# LPC54S018M register map
Vendor: nxp.com; File version: 1.0
CPU: CM4 r0p1, little endian, MPU, FPU, VTOR, 3 interrupt priority bits
Registers are 32-bit, read-write, reset 0x0 unless marked. A register's access mark holds for its fields unless they carry their own. Offsets are from the block's base; [hi:lo] are bit positions; lines under a group give offsets from that group; {n}, {i} and the like mark numbered series.

## ENET — LPC54S60x/LPC5460x Ethernet controller
Base 0x40092000
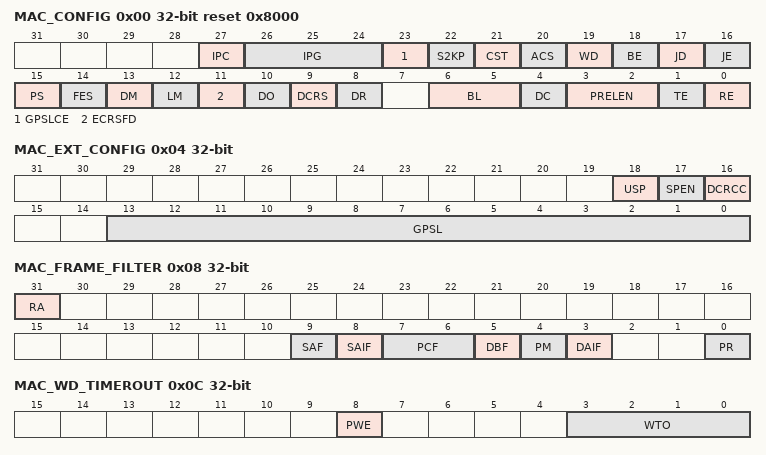
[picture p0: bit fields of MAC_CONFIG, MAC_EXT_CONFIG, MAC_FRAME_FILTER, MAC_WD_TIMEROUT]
0x00 MAC_CONFIG reset 0x8000 — MAC configuration register
  [27] IPC — Checksum Offload When set, this bit enables the IPv4 header checksum checking and IPv4 or IPv6 TCP, UDP, or ICMP payload checksum checking.
  [26:24] IPG — Inter-Packet Gap These bits control the minimum IPG between packets during transmission.
  [23] GPSLCE — Giant Packet Size Limit Control Enable When this bit is set, the MAC considers the value in GPSL field in MAC Ext Configuration register to declare a received packet as Giant packet.
  [22] S2KP — IEEE 802.
  [21] CST — CRC stripping for Type packets When this bit is set, the last four bytes (FCS) of all packets of Ether type (type field greater than 1,536) are stripped and dropped before forwarding the packet to the application.
  [20] ACS — Automatic Pad or CRC Stripping When this bit is set, the MAC strips the Pad or FCS field on the incoming packets only if the value of the length field is less than 1,536 bytes.
  [19] WD — Watchdog Disable When this bit is set, the MAC disables the watchdog timer on the receiver, and can receive frames of up to 16,384 bytes.
  [18] BE — Packet Burst Enable When this bit is set, the MAC allows packet bursting during transmission in the MII half-duplex mode.
  [17] JD — Jabber Disable When this bit is set, the MAC disables the jabber timer on the transmitter, and can transfer frames of up to 16,384 bytes.
  [16] JE — Jumbo Frame Enable When this bit is set, MAC allows Jumbo frames of 9,018 bytes (9,022 bytes for tagged frames) without reporting a giant frame error in the receive frame status.
  [15] PS ro — Portselect.
  [14] FES — Speed Indicates the speed in Fast Ethernet (MII) mode: This bit is reserved (RO) by default and is enabled only when RMII/SMII is enabled during configuration.
  [13] DM — Duplex Mode When this bit is set, the MAC operates in a Full-Duplex mode where it can transmit and receive simultaneously.
  [12] LM — Loopback Mode When this bit is set, the MAC operates in loopback mode at MII.
  [11] ECRSFD — Enable Carrier Sense Before Transmission in Full-Duplex Mode When this bit is set, the MAC transmitter checks the CRS signal before packet transmission in the full-duplex mode.
  [10] DO — Disable Receive Own When this bit is set, the MAC disables the reception of frames when the gmii_txen_o is asserted in Half-Duplex mode.
  [9] DCRS — Disable Carrier Sense During Transmission When this bit is set, the MAC transmitter ignores the MII CRS signal during packet transmission in the half-duplex mode.
  [8] DR — Disable Retry When this bit is set, the MAC will attempt only one transmission.
  [6:5] BL — Back-Off Limit The Back-Off limit determines the random integer number (r) of slot time delays (4,096 bit times for 1000 Mbps and 512 bit times for 10/100 Mbps) the MAC waits before rescheduling a transmission attempt during retries after a collision.
  [4] DC — Deferral Check When this bit is set, the deferral check function is enabled in the MAC.
  [3:2] PRELEN — Preamble Length for Transmit packets These bits control the number of preamble bytes that are added to the beginning of every Tx packet.
  [1] TE — Transmitter Enable When this bit is set, the transmit state machine of the MAC is enabled for transmission on the MII.
  [0] RE — Receiver Enable When this bit is set, the receiver state machine of the MAC is enabled for receiving frames from the MII.
0x04 MAC_EXT_CONFIG
  [18] USP — Unicast Slow Protocol Packet Detect When this bit is set, the MAC detects the Slow Protocol packets with unicast address of the station specified in the MAC Address High Table 747 and MAC Address Low Table 748 registers.
  [17] SPEN — Slow Protocol Detection Enable When this bit is set, MAC processes the Slow Protocol packets (Ether Type 0x8809) and provides the Rx status.
  [16] DCRCC — Disable CRC Checking for Received Packets When this bit is set, the MAC receiver does not check the CRC field in the received packets.
  [13:0] GPSL — Giant Packet Size Limit If the received packet size is greater than the value programmed in this field in units of bytes, the MAC declares the received packet as Giant packet.
0x08 MAC_FRAME_FILTER
  [31] RA — Receive all When this bit is set, the MAC Receiver module passes to the Application all frames received irrespective of whether they pass the address filter.
  [9] SAF ro — Source Address Filter Enable When this bit is set, the MAC compares the SA field of the received packets with the values programmed in the enabled SA registers.
  [8] SAIF ro — SA Inverse Filtering When this bit is set, the Address Check block operates in the inverse filtering mode for SA address comparison.
  [7:6] PCF — Pass Control Frames These bits control the forwarding of all control frames (including unicast and multicast PAUSE frames).
  [5] DBF — Disable Broadcast Frames When this bit is set, the AFM module filters all incoming broadcast frames.
  [4] PM — Pass All Multicast When set, this bit indicates that all received frames with a multicast destination address (first bit in the destination address field is '1') are passed.
  [3] DAIF — DA Inverse Filtering When this bit is set, the Address Check block operates in inverse filtering mode for the DA address comparison for both unicast and multicast frames.
  [0] PR — Promiscuous Mode When this bit is set, the Address Filter module passes all incoming frames regardless of its destination or source address.
0x0C MAC_WD_TIMEROUT — MAC watchdog Timeout register
  [8] PWE — Programmable Watchdog Enable When this bit is set and the WD bit of the MAC Configuration register Table 722 is reset, the WTO field is used as watchdog timeout for a received packet.
  [3:0] WTO — Watchdog Timeout When the PWE bit is set and the WD bit of the MAC Configuration register Table 722 is reset, this field is used as watchdog timeout for a received packet.
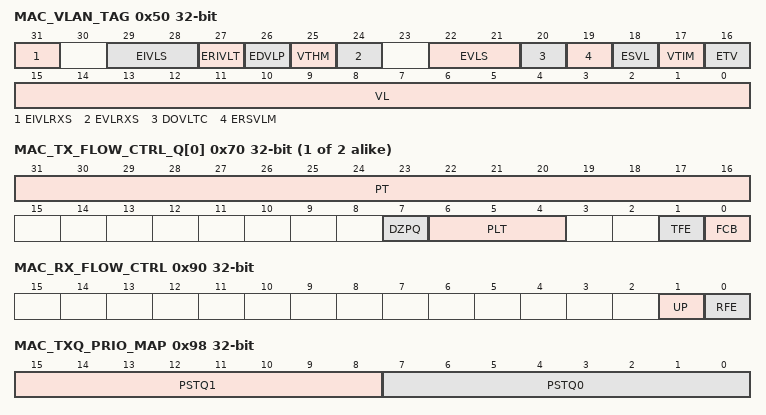
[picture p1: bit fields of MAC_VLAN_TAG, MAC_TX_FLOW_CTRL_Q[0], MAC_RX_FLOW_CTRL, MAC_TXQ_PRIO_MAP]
0x50 MAC_VLAN_TAG (reset mask 0xFFFF)
  [31] EIVLRXS — Enable Inner VLAN Tag in Rx Status.
  [29:28] EIVLS — Enable Inner VLAN Tag Stripping on Receive.
  [27] ERIVLT — Enable Inner VLAN Tag.
  [26] EDVLP — Enable Double VLAN Processing.
  [25] VTHM — Disable VLAN Type Check.
  [24] EVLRXS — Enable VLAN Tag in Rx status.
  [22:21] EVLS — Enable VLAN Tag Stripping on Receive.
  [20] DOVLTC — Disable VLAN Type Check.
  [19] ERSVLM — Enable Receive S-VLAN Match.
  [18] ESVL — Enable S-VLAN.
  [17] VTIM — VLAN Tag Inverse Match Enable.
  [16] ETV — Enable 12-Bit VLAN Tag Comparison.
  [15:0] VL — VLAN Tag Identifier for Receive Packets.
{0x70+4i} MAC_TX_FLOW_CTRL_Q[{i}] (i=0..1) — Transmit flow control register
  [31:16] PT — Pause time This field holds the value to be used in the Pause Time field in the transmit control frame.
  [7] DZPQ — Disable Zero-Quanta Pause When set, this bit disables the automatic generation of Zero-Quanta Pause Control frames on the deassertion of the flow-control signal from the FIFO layer.
  [6:4] PLT — Pause Low Threshold This field configures the threshold of the PAUSE timer at which the input flow control signal is checked for automatic retransmission of PAUSE Frame.
  [1] TFE — Transmit Flow Control Enable In Full-Duplex mode, when this bit is set, the MAC enables the flow control operation to transmit Pause frames.
  [0] FCB — Flow Control Busy/Backpressure Activate This register field can be read by the application (Read), can be set to 1 by the application with a register write of 1 (Write Set), and is cleared to 0 by the core (Self Clear).
0x90 MAC_RX_FLOW_CTRL — Receive flow control register
  [1] UP — Unicast Pause Packet Detect A pause packet is processed when it has the unique multicast address specified in the IEEE 802.
  [0] RFE — Receive Flow Control Enable When this bit is set and the MAC is operating in full-duplex mode, the MAC decodes the received Pause packet and disables its transmitter for a specified (Pause) time.
0x98 MAC_TXQ_PRIO_MAP
  [15:8] PSTQ1 — Priorities Selected in Transmit Queue 1 This bit is similar to the PSTQ0 bit.
  [7:0] PSTQ0 — Priorities Selected in Transmit Queue 0 This field holds the priorities assigned to Tx Queue 0 by the software.
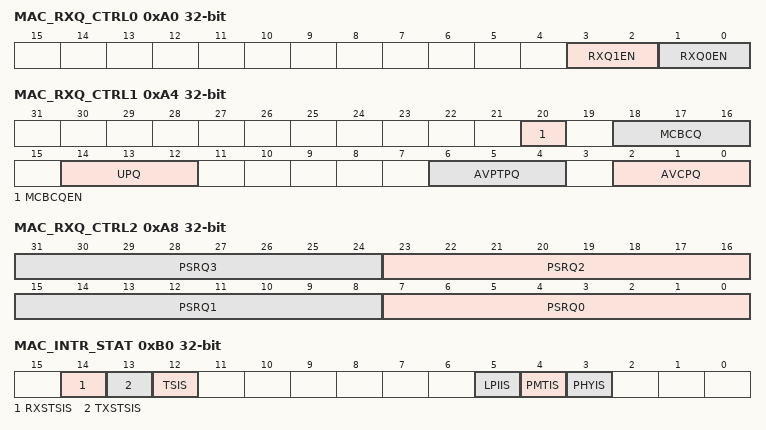
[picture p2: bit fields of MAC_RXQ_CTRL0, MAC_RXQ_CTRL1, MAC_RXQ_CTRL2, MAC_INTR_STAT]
0xA0 MAC_RXQ_CTRL0 — Receive Queue Control 0 register 0x0000
  [3:2] RXQ1EN — Receive Queue 1 Enable.
  [1:0] RXQ0EN — Receive Queue 0 Enable.
0xA4 MAC_RXQ_CTRL1 — Receive Queue Control 0 register 0x0000
  [20] MCBCQEN — Multicast and Broadcast Queue Enable.
  [18:16] MCBCQ — Multicast and Broadcast Queue.
  [14:12] UPQ — Untagged Packet Queue.
  [6:4] AVPTPQ — AV PTP Packets Queue.
  [2:0] AVCPQ — AV Untagged Control Packets Queue.
0xA8 MAC_RXQ_CTRL2 — Receive Queue Control 0 register 0x0000
  [8n+7:8n] PSRQ{n} (n=0..3) — Priorities Selected in the Receive Queue {n}.
0xB0 MAC_INTR_STAT ro — Interrupt status register 0x0000
  [14] RXSTSIS — Receive Status Interrupt.
  [13] TXSTSIS — Transmit Status Interrupt.
  [12] TSIS — Timestamp interrupt status.
  [5] LPIIS — LPI Interrupt Status.
  [4] PMTIS — PMT Interrupt Status.
  [3] PHYIS — PHY Interrupt.
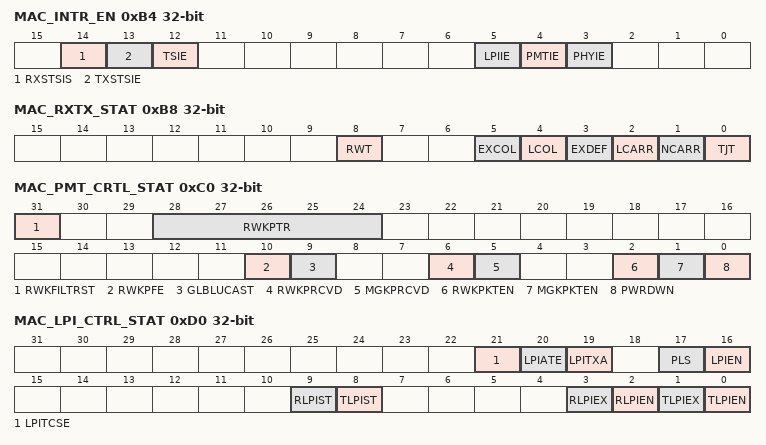
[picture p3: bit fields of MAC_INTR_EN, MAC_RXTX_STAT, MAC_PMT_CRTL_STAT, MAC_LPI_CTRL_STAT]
0xB4 MAC_INTR_EN — Interrupt enable register 0x0000
  [14] RXSTSIS — Receive Status Interrupt Enable.
  [13] TXSTSIE — Transmit Status Interrupt Enable.
  [12] TSIE — Timestamp Interrupt Enable.
  [5] LPIIE — LPI Interrupt Enable.
  [4] PMTIE — PMT Interrupt Enable.
  [3] PHYIE — PHY Interrupt Enable.
0xB8 MAC_RXTX_STAT ro — Receive Transmit Status register
  [8] RWT — Receive Watchdog Timeout This bit is set when a packet with length greater than 2,048 bytes is received (10,240 bytes when Jumbo Packet mode is enabled) and the WD bit is reset in the MAC Configuration register Table 722.
  [5] EXCOL — Excessive Collisions When the DTXSTS bit is set in the MTL Operation Mode register Table 758, this bit indicates that the transmission aborted after 16 successive collisions while attempting to transmit the current packet.
  [4] LCOL — Late Collision When the DTXSTS bit is set in the MTL Operation Mode register Table 758, this bit indicates that the packet transmission aborted because a collision occurred after the collision window (64 bytes including Preamble in MII mode).
  [3] EXDEF — Excessive Deferral When the DTXSTS bit is set in the MTL Operation Mode register Table 758 and the DC bit is set in the MAC Configuration register Table 758, this bit indicates that the transmission ended because of excessive deferral of over 24,288 bit times (155,680 when Jumbo packet is enabled).
  [2] LCARR — Loss of Carrier When the DTXSTS bit is set in the MTL Operation Mode register Table 758, this bit indicates that the loss of carrier occurred during packet transmission, that is, the PHY Carrier signal was inactive for one or more transmission clock periods during packet transmission.
  [1] NCARR — No Carrier When the DTXSTS bit is set in the MTL Operation Mode register Table 758, this bit indicates that the carrier signal from the PHY is not present at the end of preamble transmission.
  [0] TJT — PHY Interrupt Enable When this bit is set, it enables the assertion of the interrupt signal because of the setting of PHYIS bit in MAC Interrupt Status register Table 731.
0xC0 MAC_PMT_CRTL_STAT
  [31] RWKFILTRST — Remote Wake-Up Packet Filter Register Pointer Reset When this bit is set, the remote wake-up packet filter register pointer is reset to 3'b000.
  [28:24] RWKPTR — Remote Wake-up FIFO Pointer This field gives the current value (0 to 7) of the Remote Wake-up Packet Filter register pointer.
  [10] RWKPFE — Remote Wake-up Packet Forwarding Enable When this bit is set along with RWKPKTEN, the MAC receiver drops all received frames until it receives the expected wake-up frame.
  [9] GLBLUCAST — Global Unicast When this bit set, any unicast packet filtered by the MAC (DAF) address recognition is detected as a remote wake-up packet.
  [6] RWKPRCVD ro — Remote Wake-Up Packet Received.
  [5] MGKPRCVD ro — Magic Packet Received.
  [2] RWKPKTEN ro — Remote Wake-Up Packet Enable When this bit is set, a power management event is generated when the MAC receives a remote wake-up packet.
  [1] MGKPKTEN ro — Magic Packet Enable.
  [0] PWRDWN ro — Transmit LPI Entry When this bit is set, it indicates that the MAC Transmitter has entered the LPI state because of the setting of the LPIEN bit.
0xC4 MAC_RWAKE_FRFLT — Remote wake-up frame filter
  [31:0] ADDR — WKUPFMFILTER address.
0xD0 MAC_LPI_CTRL_STAT — LPI Control and Status Register
  [21] LPITCSE — LPI Tx Clock Stop Enable When this bit is set, the MAC asserts LPI Tx Clock Gating Control signal high after it enters Tx LPI mode to indicate that the Tx clock to MAC can be stopped.
  [20] LPIATE — LPI Timer Enable This bit controls the automatic entry of the MAC Transmitter into and exit out of the LPI state.
  [19] LPITXA — LPI Tx Automate This bit controls the behavior of the MAC when it is entering or coming out of the LPI mode on the Transmit side.
  [17] PLS — PHY Link Status This bit indicates the link status of the PHY.
  [16] LPIEN — LPI Enable When this bit is set, it instructs the MAC Transmitter to enter the LPI state.
  [9] RLPIST ro — Receive LPI State When this bit is set, it indicates that the MAC is receiving the LPI pattern on the MII interface.
  [8] TLPIST ro — Transmit LPI State When this bit is set, it indicates that the MAC is transmitting the LPI pattern on the MII interface.
  [3] RLPIEX ro — Receive LPI Exit When this bit is set, it indicates that the MAC Receiver has stopped receiving the LPI pattern on the MII interface, exited the LPI state, and resumed the normal reception.
  [2] RLPIEN ro — Receive LPI Entry When this bit is set, it indicates that the MAC Receiver has received an LPI pattern and entered the LPI state.
  [1] TLPIEX ro — Transmit LPI Exit When this bit is set, it indicates that the MAC transmitter exited the LPI state after the application cleared the LPIEN bit and the LPI TW Timer has expired.
  [0] TLPIEN ro — Transmit LPI Entry When this bit is set, it indicates that the MAC Transmitter has entered the LPI state because of the setting of the LPIEN bit.
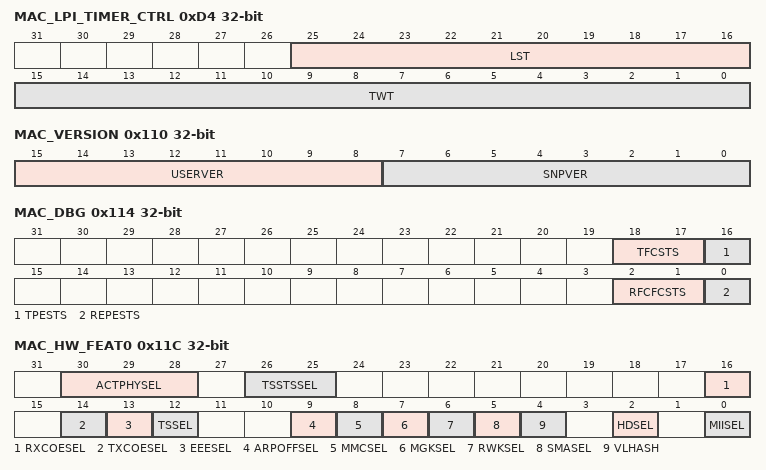
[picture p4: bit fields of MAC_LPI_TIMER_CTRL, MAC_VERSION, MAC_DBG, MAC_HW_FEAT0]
0xD4 MAC_LPI_TIMER_CTRL — LPI Timers Control register
  [25:16] LST — LPI LS Timer This field specifies the minimum time (in milliseconds) for which the link status from the PHY should be up (OKAY) before the LPI pattern can be transmitted to the PHY.
  [15:0] TWT — LPI TW Timer This field specifies the minimum time (in microseconds) for which the MAC waits after it stops transmitting the LPI pattern to the PHY and before it resumes the normal transmission.
0xD8 MAC_LPI_ENTR_TIMR — LPI entry Timer register
  [19:3] LPIET — LPI Entry Timer This field specifies the time in microseconds the MAC will wait to enter LPI mode, after it has transmitted all the frames.
0xDC MAC_1US_TIC_COUNTR
  [11:0] TIC_1US_CNTR — 1US TIC Counter The application must program this counter so that the number of clock cycles of CSR clock is 1us.
0x110 MAC_VERSION ro (reset mask 0x20FF)
  [15:8] USERVER — User defined version.
  [7:0] SNPVER — NXP defined version.
0x114 MAC_DBG ro — MAC debug register
  [18:17] TFCSTS — MAC Transmit Packet Controller Status This field indicates the state of the MAC Transmit Packet Controller module.
  [16] TPESTS — MAC MII Transmit Protocol Engine Status When this bit is set, it indicates that the MAC or MII transmit protocol engine is actively transmitting data, and it is not in the Idle state.
  [2:1] RFCFCSTS — MAC Receive Packet Controller FIFO Status When this bit is set, this field indicates the active state of the small FIFO Read and Write controllers of the MAC Receive Packet Controller module.
  [0] REPESTS — MAC MII Receive Protocol Engine Status When this bit is set, it indicates that the MAC MII receive protocol engine is actively receiving data, and it is not in the Idle state.
0x11C MAC_HW_FEAT0 ro — MAC hardware feature register 0x0201
  [30:28] ACTPHYSEL — Active PHY Selected.
  [26:25] TSSTSSEL — Timestamp System Time Source.
  [16] RXCOESEL — Receive Checksum Offload Support.
  [14] TXCOESEL — Transmit Checksum Offload Support.
  [13] EEESEL — Energy Efficient Ethernet Support .
  [12] TSSEL — IEEE 1588-2008 Timestamp support .
  [9] ARPOFFSEL — ARP Offload Enabled.
  [8] MMCSEL — RMON Module Enable.
  [7] MGKSEL — PMT magic packet detection.
  [6] RWKSEL — PMT Remote Wake-up Packet Detection.
  [5] SMASEL — SMA (MDIO) Interface.
  [4] VLHASH — Hash Table Based Filtering option.
  [2] HDSEL — Half-duplex Support.
  [0] MIISEL — 10 or 100 Mbps Support.
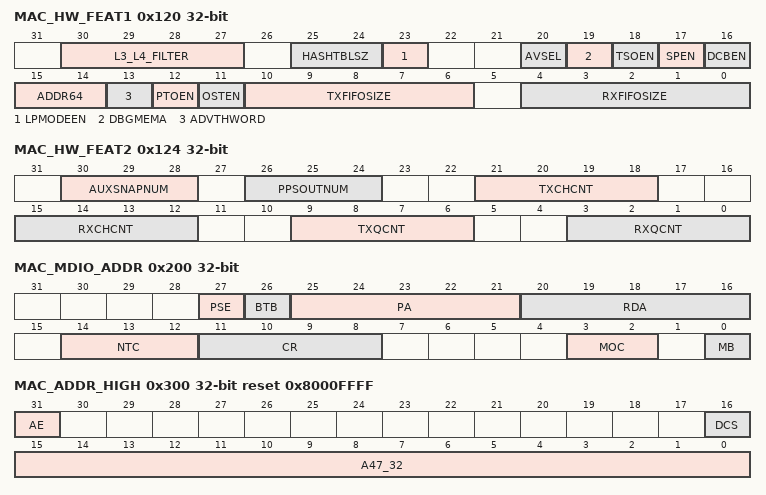
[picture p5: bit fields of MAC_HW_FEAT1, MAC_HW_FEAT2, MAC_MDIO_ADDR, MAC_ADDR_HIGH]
0x120 MAC_HW_FEAT1 ro — MAC hardware feature register 0x0201
  [30:27] L3_L4_FILTER — Total Number of L3 and L4 Filters .
  [25:24] HASHTBLSZ — Hash Table Size.
  [23] LPMODEEN — Low Power Mode Feature Support .
  [20] AVSEL — Audio Video Bridging Feature.
  [19] DBGMEMA — DMA Debug Register Feature.
  [18] TSOEN — TCP Segment Offload Feature.
  [17] SPEN — Split Header Structure feature.
  [16] DCBEN — Data Center Bridging feature.
  [15:14] ADDR64 — Address width.
  [13] ADVTHWORD — IEEE 1588 High Word Register Feature.
  [12] PTOEN — PTP OffLoad Feature.
  [11] OSTEN — One-Step Timestamping Feature.
  [10:6] TXFIFOSIZE — MTL Transmit FIFO Size.
  [4:0] RXFIFOSIZE — MTL Receive FIFO Size.
0x124 MAC_HW_FEAT2 ro — MAC hardware feature register 0x0201
  [30:28] AUXSNAPNUM — Number of Auxiliary Snapshot Inputs.
  [26:24] PPSOUTNUM — Number of PPS Outputs.
  [21:18] TXCHCNT — Number of DMA Transmit Channels.
  [15:12] RXCHCNT — Number of DMA Receive Channels.
  [9:6] TXQCNT — Number of MTL Transmit Queues.
  [3:0] RXQCNT — Number of MTL Receive Queues.
0x200 MAC_MDIO_ADDR — MIDO address Register
  [27] PSE — Preamble Suppression Enable When this bit is set, the SMA will suppress the 32-bit preamble and transmit MDIO frames with only 1 preamble bit.
  [26] BTB — Back to Back transactions When this bit is set and the NTC has value greater than 0, then the MAC will inform the completion of a read or write command at the end of frame transfer (before the trailing clocks are transmitted).
  [25:21] PA — Physical Layer Address This field indicates which PHY devices (out of 32 devices) the MAC is accessing.
  [20:16] RDA — Register/Device Address These bits select the PHY register in selected PHY device.
  [14:12] NTC — Number of Training Clocks This field controls the number of trailing clock cycles generated on MDC after the end of transmission of MDIO frame.
  [11:8] CR — CSR Clock Range.
  [3:2] MOC — MII Operation Command.
  [0] MB — MII busy.
0x204 MAC_MDIO_DATA — MDIO Data register
  [15:0] MD — MII Data This field contains the 16-bit data value read from the PHY after a Management Read operation or the 16-bit data value to be written to the PHY before a Management Write operation.
0x300 MAC_ADDR_HIGH reset 0x8000FFFF — MAC address0 high register
  [31] AE ro — Address Enable.
  [16] DCS — DMA Channel Select This field contains the DMA Channel number to which the Rx packet whose DA matches the MAC Address content is routed.
  [15:0] A47_32 — MAC Address0 [47:32] This field contains the upper 16 bits (47:32) of the 6-byte first MAC address.
0x304 MAC_ADDR_LOW reset 0xFFFFFFFF — MAC address0 low register
  [31:0] A31_0 — MAC Address0 [31:0] This field contains the lower 32 bits of the 6-byte first MAC address.
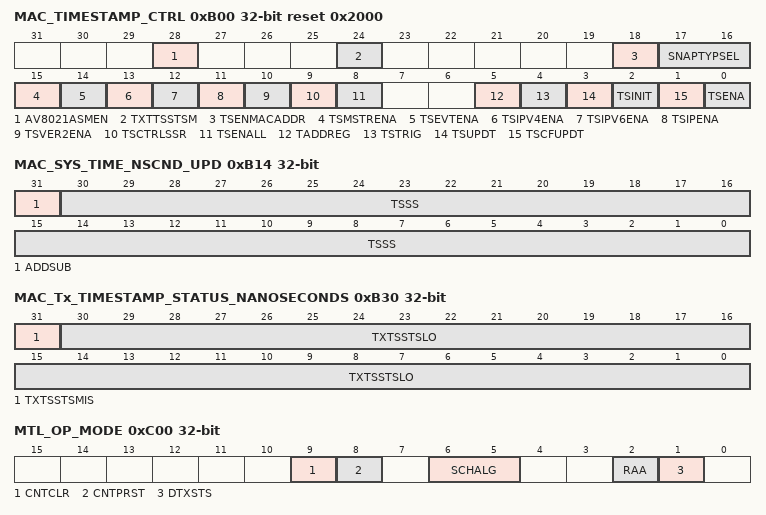
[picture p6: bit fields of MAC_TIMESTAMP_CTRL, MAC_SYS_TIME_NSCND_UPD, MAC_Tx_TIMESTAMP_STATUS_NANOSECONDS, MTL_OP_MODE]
0xB00 MAC_TIMESTAMP_CTRL reset 0x2000 — Time stamp control register
  [28] AV8021ASMEN — AV 802.
  [24] TXTTSSTSM — Transmit Timestamp Status Mode When this bit is set, the MAC overwrites the earlier transmit timestamp status even if it is not read by the software.
  [18] TSENMACADDR — Enable MAC Address for PTP Packet Filtering When this bit is set, the DA MAC address (that matches any MAC Address register) is used to filter the PTP packets when PTP is directly sent over Ethernet.
  [17:16] SNAPTYPSEL — Select PTP packets for Taking Snapshots These bits, along with Bits 15 and 14, decide the set of PTP packet types for which snapshot needs to be taken.
  [15] TSMSTRENA — Enable Snapshot for Messages Relevant to Master When this bit is set, the snapshot is taken only for the messages that are relevant to the master node.
  [14] TSEVTENA — Enable Timestamp Snapshot for Event Messages When this bit is set, the timestamp snapshot is taken only for event messages (SYNC, Delay_Req, Pdelay_Req, or Pdelay_Resp).
  [13] TSIPV4ENA — Enable Processing of PTP Packets Sent over IPv4-UDP When this bit is set, the MAC receiver processes the PTP packets encapsulated in IPv4-UDP packets.
  [12] TSIPV6ENA — Enable Processing of PTP Packets Sent over 1Pv6-UDP When this bit is set, the MAC receiver processes the PTP packets encapsulated in IPv6-UDP packets.
  [11] TSIPENA — Enable Processing of PTP over Ethernet Packets When this bit is set, the MAC receiver processes the PTP packets encapsulated directly in the Ethernet packets.
  [10] TSVER2ENA — Enable PTP Packet Processing for Version 2 Format When this bit is set, the IEEE 1588 version 2 format is used to process the PTP packets.
  [9] TSCTRLSSR — Timestamp Digital or Binary Rollover Control When this bit is set, the Timestamp Low register rolls over after 0x3B9AC9FF value (that is, 1 nanosecond accuracy) and increments the timestamp (High) seconds.
  [8] TSENALL — Enable Timestamp for All Packets When this bit is set, the timestamp snapshot is enabled for all packets received by the MAC.
  [5] TADDREG — Update Addend Register When this bit is set, the content of the Timestamp Addend register is updated in the PTP block for fine correction.
  [4] TSTRIG — Enable Timestamp Interrupt Trigger When this bit is set, the timestamp interrupt is generated when the System Time becomes greater than the value written in the Target Time register.
  [3] TSUPDT — Update Timestamp When this bit is set, the system time is updated (added or subtracted) with the value specified in MAC System Time Seconds Update Table 753 and MAC System Time Nanoseconds Update Table 754.
  [2] TSINIT — Initialize Timestamp When this bit is set, the system time is initialized (overwritten) with the value specified in the MAC Register 80 (System Time Seconds Update.
  [1] TSCFUPDT — Fine or Coarse Timestamp Update When this bit is set, the Fine method is used to update system timestamp.
  [0] TSENA — Enable Timestamp When this bit is set, the timestamp is added for Transmit and Receive packets.
0xB04 MAC_SUB_SCND_INCR — Sub-second increment register
  [23:16] SSINC — Sub-second increment value.
0xB08 MAC_SYS_TIME_SCND ro — System time seconds register
  [31:0] TSS — Time stamp second The value in this field indicates the current value in seconds of the System Time maintained by the MAC.
0xB0C MAC_SYS_TIME_NSCND ro — System time nanoseconds register
  [30:0] TSSS — Time stamp sub seconds The value in this field has the sub second representation of time, with an accuracy of 0.
0xB10 MAC_SYS_TIME_SCND_UPD
  [31:0] TSS — Time stamp second The value in this field indicates the time, in seconds, to be initialized or added to the system time.
0xB14 MAC_SYS_TIME_NSCND_UPD
  [31] ADDSUB — Add or subtract time When this bit is set, the time value is subtracted with the contents of the update register.
  [30:0] TSSS — Time stamp sub seconds The value in this field has the sub second representation of time, with an accuracy of 0.
0xB18 MAC_SYS_TIMESTMP_ADDEND — Time stamp addend register
  [31:0] TSAR — Time stamp addend This register indicates the 32-bit time value to be added to the Accumulator register to achieve time synchronization.
0xB1C MAC_SYS_TIME_HWORD_SCND
  [15:0] TSHWR — Time stamp higher word Contains the most significant 16-bits of the Time stamp seconds value.
0xB20 MAC_SYS_TIMESTMP_STAT ro — Time stamp status register
  [0] TSSOVF — Time stamp seconds overflow When set, indicates that the seconds value of the Time stamp has overflowed beyond 0xFFFF_FFFF.
0xB30 MAC_Tx_TIMESTAMP_STATUS_NANOSECONDS ro — Tx timestamp status nanoseconds
  [31] TXTSSTSMIS — Transmit timestamp status missed.
  [30:0] TXTSSTSLO — Transmit timestamp status low.
0xB34 MAC_Tx_TIMESTAMP_STATUS_SECONDS ro — Tx timestamp status seconds
  [31:0] TXTSSTSHI — Transmit timestamp status high.
0xB58 MAC_TIMESTAMP_INGRESS_CORR_NANOSECOND — Timestamp ingress correction
  [31:0] TSIC — Transmit ingress correction.
0xB5C MAC_TIMESTAMP_EGRESS_CORR_NANOSECOND — Timestamp egress correction
  [31:0] TSEC — Transmit egress correction.
0xC00 MTL_OP_MODE — MTL Operation Mode Register
  [9] CNTCLR — Counters Reset When this bit is set, all counters are reset.
  [8] CNTPRST — Counters Preset When this bit is set, MTL TxQ0 Underflow register (Table 762) and MTL_TxQ1_Underflow (Table 762) registers are initialized/preset to 0x7F0.
  [6:5] SCHALG — Tx Scheduling Algorithm This field indicates the algorithm for Tx scheduling: 0x00: WRR algorithm 0x1: Reserved 0x2: Reserved 0x3: Strict priority algorithm.
  [2] RAA ro — Receive Arbitration Algorithm This field is used to select the arbitration algorithm for the Rx side.
  [1] DTXSTS — Drop Transmit Status When this bit is set, the Tx packet status received from the MAC is dropped in the MTL.
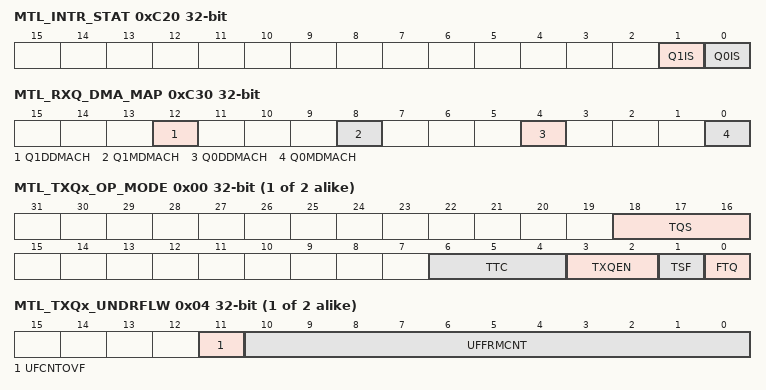
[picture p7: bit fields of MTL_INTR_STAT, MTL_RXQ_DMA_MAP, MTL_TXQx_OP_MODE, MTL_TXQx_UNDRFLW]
0xC20 MTL_INTR_STAT ro — MTL Interrupt Status register
  [1] Q1IS — Queue 1 Interrupt status This bit indicates that there is an interrupt from Queue 1.
  [0] Q0IS — Queue 0 Interrupt status This bit indicates that there is an interrupt from Queue 0.
0xC30 MTL_RXQ_DMA_MAP — MTL Receive Queue and DMA Channel Mapping register
  [12] Q1DDMACH — Queue 1 Enabled for DA-based DMA Channel Selection When set, this bit indicates that the packets received in Queue 1 are routed to a particular DMA channel as decided in the MAC Receiver based on the DMA channel number programmed in the L3-L4 filter registers, or the Ethernet DA address.
  [8] Q1MDMACH — Queue 1 Mapped to DMA Channel This field controls the routing of the received packet in Queue 1 to the DMA channel: 0: DMA Channel 0 1: DMA Channel 1 This field is valid when the Q1DDMACH field is reset.
  [4] Q0DDMACH — Queue 0 Enabled for DA-based DMA Channel Selection When set, this bit indicates that the packets received in Queue 0 are routed to a particular DMA channel as decided in the MAC Receiver based on the DMA channel number programmed in the L3-L4 filter registers, or the Ethernet DA address.
  [0] Q0MDMACH — Queue 0 Mapped to DMA Channel This field controls the routing of the packet received in Queue 0 to the DMA channel: 0: DMA Channel 0 1: DMA Channel 1 This field is valid when the Q0DDMACH field is reset.
{0xD00+0x40*i} MTL_QUEUE[{i}] (i=0..1) group
  0x00 MTL_TXQx_OP_MODE — MTL TxQx Operation Mode register
    [18:16] TQS — Transmit Queue Size This field indicates the size of the allocated Transmit queues in blocks of 256 bytes.
    [6:4] TTC — Transmit Threshold Control These bits control the threshold level of the MTL Tx Queue.
    [3:2] TXQEN — Transmit Queue Enable This field is used to enable/disable the transmit queue 0.
    [1] TSF — Transmit Store and Forward When this bit is set, the transmission starts when a full packet resides in the MTL Tx queue.
    [0] FTQ — Flush Transmit Queue When this bit is set, the Tx queue controller logic is reset to its default values.
  0x04 MTL_TXQx_UNDRFLW ro — MTL TxQx Underflow register
    [11] UFCNTOVF — Overflow Bit for Underflow Packet Counter This bit is set every time the Tx queue Underflow Packet Counter field overflows, that is, it has crossed the maximum count.
    [10:0] UFFRMCNT — Underflow Packet Counter This field indicates the number of packets aborted by the controller because of Tx Queue Underflow.
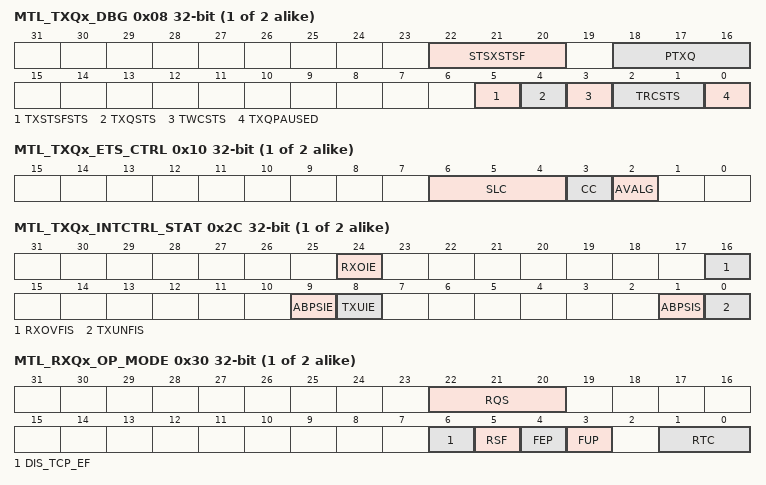
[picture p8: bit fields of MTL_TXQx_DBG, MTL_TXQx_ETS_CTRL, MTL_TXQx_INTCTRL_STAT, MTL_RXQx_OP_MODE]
  0x08 MTL_TXQx_DBG ro — MTL TxQx Debug register
    [22:20] STSXSTSF — Number of Status Words in Tx Status FIFO of Queue This field indicates the current number of status in the Tx Status FIFO of this queue.
    [18:16] PTXQ — Number of Packets in the Transmit Queue This field indicates the current number of packets in the Tx Queue.
    [5] TXSTSFSTS — MTL Tx Status FIFO Full Status When high, this bit indicates that the MTL Tx Status FIFO is full.
    [4] TXQSTS — MTL Tx Queue Not Empty Status When this bit is high, it indicates that the MTL Tx Queue is not empty and some data is left for transmission.
    [3] TWCSTS — MTL Tx Queue Write Controller Status When high, this bit indicates that the MTL Tx Queue Write Controller is active, and it is transferring the data to the Tx Queue.
    [2:1] TRCSTS — MTL Tx Queue Read Controller Status This field indicates the state of the Tx Queue Read Controller: 00: Idle state 01: Read state (transferring data to the MAC transmitter) 10: Waiting for pending Tx Status from the MAC transmitter 11: Flushing the Tx queue because of the Packet Abort request from the MAC.
    [0] TXQPAUSED — Transmit Queue in Pause When this bit is high and the Rx flow control is enabled, it indicates that the Tx Queue is in the Pause condition (in the full-duplex only mode) because of the following: - Reception of the PFC packet for the priorities assigned to the Tx Queue when PFC is enabled - Reception of 802.
  0x10 MTL_TXQx_ETS_CTRL — MTL TxQx ETS control register, only TxQ1 support
    [6:4] SLC ro — Credit Control.
    [3] CC — Credit Control.
    [2] AVALG — AV Algorithm.
  0x14 MTL_TXQx_ETS_STAT — MTL TxQx ETS Status register
    [23:0] ABS ro — Average Bits per Slot.
  0x18 MTL_TXQx_QNTM_WGHT
    [20:0] ISCQW — Average Bits per Slot.
  0x1C MTL_TXQx_SNDSLP_CRDT — MTL TxQx SendSlopCredit register, only TxQ1 support
    [13:0] SSC — sendSlopeCredit.
  0x20 MTL_TXQx_HI_CRDT — MTL TxQx hiCredit register, only TxQ1 support
    [28:0] HC — hiCredit.
  0x24 MTL_TXQx_LO_CRDT — MTL TxQx loCredit register, only TxQ1 support
    [28:0] LC — loCredit.
  0x2C MTL_TXQx_INTCTRL_STAT
    [24] RXOIE — Receive Queue Overflow Interrupt Enable When this bit is set, the Receive Queue Overflow interrupt is enabled.
    [16] RXOVFIS — Receive Queue Overflow Interrupt Status This bit indicates that the Receive Queue had an overflow while receiving the packet.
    [9] ABPSIE — Average Bits Per Slot Interrupt Enable When this bit is set, the MAC asserts the interrupt when the average bits per slot status is updated.
    [8] TXUIE — Transmit Queue Underflow Interrupt Enable When this bit is set, the Transmit Queue Underflow interrupt is enabled.
    [1] ABPSIS — Average Bits Per Slot Interrupt Status When set, this bit indicates that the MAC has updated the ABS value.
    [0] TXUNFIS — Transmit Queue Underflow Interrupt Status This bit indicates that the Transmit Queue had an underflow while transmitting the packet.
  0x30 MTL_RXQx_OP_MODE — MTL RxQx Operation Mode register
    [22:20] RQS — This field indicates the size of the allocated Receive queues in blocks of 256 bytes.
    [6] DIS_TCP_EF — Disable Dropping of TCP/IP Checksum Error Packets When this bit is set, the MAC does not drop the packets which only have the errors detected by the Receive Checksum Offload engine.
    [5] RSF — Receive Queue Store and Forward When this bit is set, the ethernet block on this chip reads a packet from the Rx queue only after the complete packet has been written to it, ignoring the RTC field of this register.
    [4] FEP — Forward Error Packets When this bit is reset, the Rx queue drops packets with error status (CRC error, Mll_ER, watchdog timeout, or overflow).
    [3] FUP — Forward Undersized Good Packets When this bit is set, the Rx queue forwards the undersized good packets (packets with no error and length less than 64 bytes), including pad-bytes and CRC.
    [1:0] RTC — Receive Queue Threshold Control These bits control the threshold level of the MTL Rx queue (in bytes): 00: 64 01: 32 10: 96 11: 128 The packet received is transferred to the application or DMA when the packet size within the MTL Rx queue is larger than the threshold.
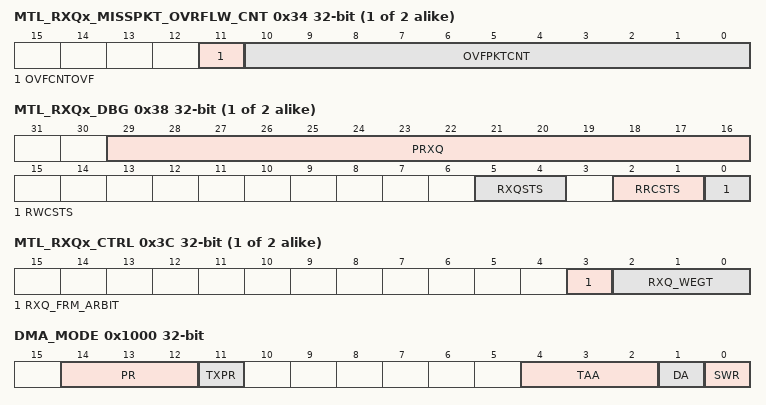
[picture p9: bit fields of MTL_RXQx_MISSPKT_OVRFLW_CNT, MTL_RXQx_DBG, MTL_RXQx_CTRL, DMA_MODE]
  0x34 MTL_RXQx_MISSPKT_OVRFLW_CNT — MTL RxQx Missed Packet Overflow Counter register
    [11] OVFCNTOVF ro — Overflow Counter Overflow Bit When set, this bit indicates that the Rx Queue Overflow Packet Counter field crossed the maximum limit.
    [10:0] OVFPKTCNT ro — Overflow Packet Counter This field indicates the number of packets discarded by the Ethernet block because of Receive queue overflow.
  0x38 MTL_RXQx_DBG — MTL RxQx Debug register
    [29:16] PRXQ ro — Number of Packets in Receive Queue This field indicates the current number of packets in the Rx Queue.
    [5:4] RXQSTS ro — MTL Rx Queue Fill-Level Status This field gives the status of the fill-level of the Rx Queue: 0x0: Rx Queue empty 0x1: Rx Queue fill-level below flow-control deactivate threshold 0x2: Rx Queue fill-level above flow-control activate threshold 0x3: Rx Queue full.
    [2:1] RRCSTS ro — MTL Rx Queue Read Controller State This field gives the state of the Rx queue Read controller: 00: Idle state 01: Reading packet data 10: Reading packet status (or timestamp) 11: Flushing the packet data and status.
    [0] RWCSTS ro — MTL Rx Queue Write Controller Active Status When high, this bit indicates that the MTL Rx queue Write controller is active, and it is transferring a received packet to the Rx Queue.
  0x3C MTL_RXQx_CTRL — MTL RxQx Control register
    [3] RXQ_FRM_ARBIT — Receive Queue Packet Arbitration When this bit is set, the The ethernet block drives the packet data to the ARI interface such that the entire packet data of currently-selected queue is transmitted before switching to other queue.
    [2:0] RXQ_WEGT — Receive Queue Weight This field indicates the weight assigned to the Rx Queue 0.
0x1000 DMA_MODE
  [14:12] PR — Priority Ratio These bits control the priority ratio in weighted round-robin arbitration between the Rx DMA and Tx DMA.
  [11] TXPR — Transmit Priority When set, this bit indicates that the Tx DMA has higher priority than the Rx DMA during arbitration for the system-side bus.
  [4:2] TAA — Transmit Arbitration Algorithm This field is used to select the arbitration algorithm for the Transmit side when multiple Tx DMAs are selected.
  [1] DA — DMA Tx or Rx Arbitration Scheme This bit specifies the arbitration scheme between the Transmit and Receive paths of all channels: The Tx path has priority over the Rx path when the TXPR bit is set.
  [0] SWR — Software Reset When this bit is set, the MAC and the OMA controller reset the logic and all internal registers of the OMA, MTL, and MAC.
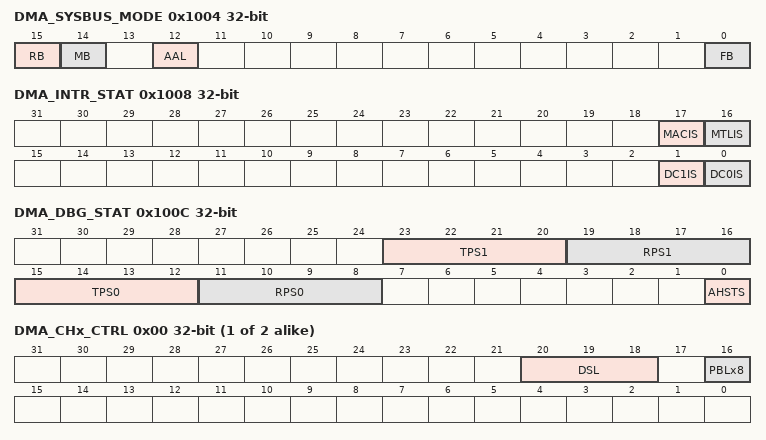
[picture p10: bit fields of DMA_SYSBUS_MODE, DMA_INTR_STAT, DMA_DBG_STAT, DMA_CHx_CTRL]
0x1004 DMA_SYSBUS_MODE — DMA System Bus mode
  [15] RB — Rebuild INCRx Burst When this bit is set high and the AHB master gets SPLIT, RETRY, or EarlyBurst Termination (EBT) response, the AHB master interface rebuilds the pending beats of any initiated burst transfer with INCRx and SINGLEtransfers.
  [14] MB — Mixed Burst When this bit is set high and the FB bit is low, the AHB master performs undefined bursts transfers (INCR) for burst length of 16 or more.
  [12] AAL — Address-Aligned Beats When this bit is set to 1, the AHB master performs address-aligned burst transfers on Read and Write channels.
  [0] FB — Fixed Burst Length When this bit is set to 1, the AHB master will initiate burst transfers of specified length (INCRx or SINGLE).
0x1008 DMA_INTR_STAT — DMA Interrupt status
  [17] MACIS ro — MAC Interrupt Status This bit indicates an interrupt event in the MAC.
  [16] MTLIS ro — MTL Interrupt Status This bit indicates an interrupt event in the MTL.
  [1] DC1IS — DMA Channel 1 Interrupt Status This bit indicates an interrupt event in DMA Channel 1.
  [0] DC0IS — DMA Channel 0 Interrupt Status This bit indicates an interrupt event in DMA Channel 0.
0x100C DMA_DBG_STAT — DMA Debug Status
  [23:20] TPS1 ro — DMA Channel 1 Transmit Process State This field indicates the Tx DMA FSM state for Channel 1.
  [19:16] RPS1 ro — DMA Channel 1 Receive Process State This field indicates the Rx DMA FSM state for Channel 1.
  [15:12] TPS0 ro — DMA Channel 0 Transmit Process State This field indicates the Tx DMA FSM state for Channel 0: 000: Stopped (Reset or Stop Transmit Command issued) 0x1: Running (Fetching Tx Transfer) 0x2: Running (Waiting for status) 0x3: Running (Reading Data from system memory buffer and queuing it to the Tx buffer (Tx FIFO)) 0x4: Timestamp write state 0x5: Reserved for future use 0x6: Suspended (Tx Unavailable or Tx Buffer Underflow) 0x7: Running (Closing Tx ) This field does not generate an interrupt.
  [11:8] RPS0 ro — DMA Channel 0 Receive Process State This field indicates the Rx DMA FSM state for Channel 0: 0x0: Stopped (Reset or Stop Receive Command issued) 0x1: Running (Fetching Rx Transfer ) 0x2: Reserved 0x3: Running (Waiting for Rx packet) 0x4: Suspended (Rx Unavailable) 0x5: Running (Closing the Rx) 0x6: Timestamp write state 0x7: Running (Transferring the received packet data from the Rx buffer to the system memory) This field does not generate an interrupt.
  [0] AHSTS ro — AHB Master Status When high, this bit indicates that the AHB master FSMs are in the non-idle state.
{0x1100+0x80*i} DMA_CH[{i}] (i=0..1) group
  0x00 DMA_CHx_CTRL — DMA Channelx Control
    [20:18] DSL — Skip Length This bit specifies the Word, Dword, or Lword number (depending on the 32- bit, 64-bit, or 128-bit bus) to skip between two unchained s.
    [16] PBLx8 — 8xPBL mode When this bit is set, the PBL value programmed in Bits[21:16] in DMA Channel Transmit Control Table 780 is multiplied eight times.
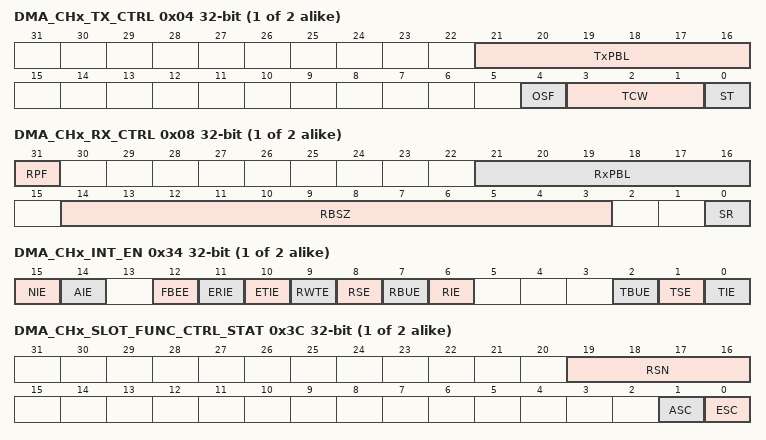
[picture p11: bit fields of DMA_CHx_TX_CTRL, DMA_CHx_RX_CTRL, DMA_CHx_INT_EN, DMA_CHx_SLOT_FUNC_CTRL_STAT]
  0x04 DMA_CHx_TX_CTRL — DMA Channelx Transmit Control
    [21:16] TxPBL — Transmit Programmable Burst Length These bits indicate the maximum number of beats to be transferred in one DMA data transfer.
    [4] OSF — Operate on Second Frame When this bit is set, it instructs the DMA to process the second packet of the Transmit data even before the status for the first packet is obtained.
    [3:1] TCW — Transmit Channel Weight This field indicates the weight assigned to the corresponding Transmit channel.
    [0] ST — Start or Stop Transmission Command When this bit is set, transmission is placed in the Running state.
  0x08 DMA_CHx_RX_CTRL — DMA Channelx Receive Control
    [31] RPF — DMA Rx Channel 0 Packet Flush When this bit is set to 1, the DMA will automatically flush the packet from the Rx Queues destined to DMA Rx Channel 0 when the DMA Rx Channel 0 is stopped after a system bus error has occurred.
    [21:16] RxPBL — Receive Programmable Burst Length These bits indicate the maximum number of beats to be transferred in one DMA data transfer.
    [14:3] RBSZ — Receive Buffer size This field indicates the size of the Rx buffers specified in bytes.
    [0] SR — Start or Stop Receive When this bit is set, the DMA tries to acquire the from the receive list and processes the incoming packets.
  0x14 DMA_CHx_TXDESC_LIST_ADDR
    [31:2] STL — Start of transmit list This field contains the base address of the first in the Transmit list.
  0x1C DMA_CHx_RXDESC_LIST_ADDR
    [31:2] SRL — Start of receive list This field contains the base address of the First in the Receive list.
  0x20 DMA_CHx_TXDESC_TAIL_PTR
    [31:2] TDTP — Transmit Tail Pointer This field contains the tail pointer for the Tx ring.
  0x28 DMA_CHx_RXDESC_TAIL_PTR
    [31:2] RDTP — Receive Tail Pointer This field contains the tail pointer for the Rx ring.
  0x2C DMA_CHx_TXDESC_RING_LENGTH
    [9:0] TDRL — Transmit Ring Length This field sets the maximum number of Tx descriptors in the circular ring.
  0x30 DMA_CHx_RXDESC_RING_LENGTH — Channelx Rx descriptor Ring Length
    [9:0] RDRL — Receive Ring Length This register sets the maximum number of Rx descriptors in the circular ring.
  0x34 DMA_CHx_INT_EN — Channelx Interrupt Enable
    [15] NIE — Normal interrupt summary enable When this bit is set, a normal interrupt is enabled.
    [14] AIE — Abnormal interrupt summary enable When this bit is set, an Abnormal Interrupt summary is enabled.
    [12] FBEE — Fatal bus error enable When this bit is set with Abnormal Interrupt Summary Enable (bit 15 in this register), the Fatal Bus Error Interrupt is enabled.
    [11] ERIE — Early receive interrupt enable When this bit is set with Normal Interrupt Summary Enable (bit 16 in this register), Early Receive Interrupt is enabled.
    [10] ETIE — Early transmit interrupt enable When this bit is set with an Abnormal Interrupt Summary Enable (bit 15 in this register), Early Transmit Interrupt is enabled.
    [9] RWTE — Receive watchdog timeout enable When this bit is set with Abnormal Interrupt Summary Enable (bit 15 in this register), the Receive Watchdog Timeout Interrupt is enabled.
    [8] RSE — Received stopped enable When this bit is set with Abnormal Interrupt Summary Enable (bit 15 in this register), Receive Stopped Interrupt is enabled.
    [7] RBUE — Receive buffer unavailable enable When this bit is set with Abnormal Interrupt Summary Enable (bit 15 in this register), Receive Buffer Unavailable Interrupt is enabled.
    [6] RIE — Receive interrupt enable When this bit is set with Normal Interrupt Summary Enable (bit 16 in this register), Receive Interrupt is enabled.
    [2] TBUE — Transmit buffer unavailable enable When this bit is set with Normal Interrupt Summary Enable (bit 16 in this register), Transmit Buffer Unavailable Interrupt is enabled.
    [1] TSE — Transmit stopped enable When this bit is set with Abnormal Interrupt Summary Enable (bit 15 in this register), Transmission Stopped Interrupt is enabled.
    [0] TIE — Transmit interrupt enable When this bit is set with Normal Interrupt Summary Enable (bit 16 in this register), Transmit Interrupt is enabled.
  0x38 DMA_CHx_RX_INT_WDTIMER — Receive Interrupt Watchdog Timer
    [7:0] RIWT — Receive Interrupt Watchdog Timer Count Indicates the number of system clock cycles multiplied by 256 for which the watchdog timer is set.
  0x3C DMA_CHx_SLOT_FUNC_CTRL_STAT — Slot Function Control and Status
    [19:16] RSN ro — Reference Slot Number This field gives the current value of the reference slot number in the DMA.
    [1] ASC — Advance Slot Check When set, this bit enables the D MA to fetch the data from the buffer when the slot number (SLOTNUM) programmed in the Tx descriptor is equal to the reference slot number given in the RSN field or, ahead of the reference slot number by up to two slots This bit is applicable only when the ESC bit is set.
    [0] ESC — Enable Slot Comparison When set, this bit enables the checking of the slot numbers programmed in the Tx descriptor with the current reference given in the RSN field.
  0x44 DMA_CHx_CUR_HST_TXDESC ro — Channelx Current Host Transmit descriptor
    [31:0] HTD — Host Transmit descriptor Address Pointer Cleared on Reset.
  0x4C DMA_CHx_CUR_HST_RXDESC ro
    [31:0] HRD — Host Receive descriptor Address Pointer Cleared on Reset.
  0x54 DMA_CHx_CUR_HST_TXBUF ro
    [31:0] HTB — Host Transmit Buffer Address Pointer Cleared on Reset.
  0x5C DMA_CHx_CUR_HST_RXBUF ro — Channelx Current Application Receive Buffer Address
    [31:0] HRB — Host Receive Buffer Address Pointer Cleared on Reset.
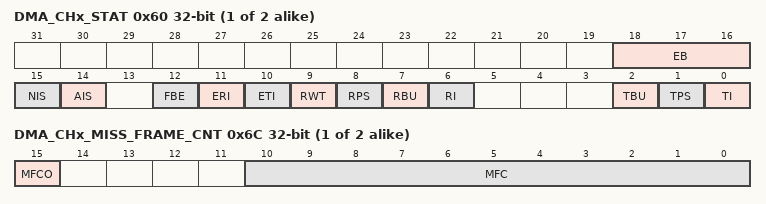
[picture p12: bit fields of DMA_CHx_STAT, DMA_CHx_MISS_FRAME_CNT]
  0x60 DMA_CHx_STAT — Channelx DMA status register
    [18:16] EB — DMA Error Bits This field indicates the type of error that caused a Bus Error.
    [15] NIS — Normal Interrupt Summary Normal Interrupt Summary bit value is the logical OR of the following bits when the corresponding interrupt bits are enabled in the DMA Channel Interrupt Enable register Table 778: Bit 0: Transmit Interrupt Bit 2: Transmit Buffer Unavailable Bit 6: Receive Interrupt Bit 11: Early Receive Interrupt Only unmasked bits (interrupts for which interrupt enable is set in DMA Channel Interrupt Enable register Table 778) affect the Normal Interrupt Summary bit.
    [14] AIS — Abnormal Interrupt Summary Abnormal Interrupt Summary bit value is the logical OR of the following when the corresponding interrupt bits are enabled in the DMA Channel Interrupt Enable register Table 778: Bit 1: Transmit Process Stopped Bit 7: Receive Buffer Unavailable Bit 8: Receive Process Stopped Bit 10: Ear1y Transmit Interrupt Bit 12: Fatal Bus Error Only unmasked bits affect the Abnormal Interrupt Summary bit.
    [12] FBE — Fatal Bus Error This bit indicates that a bus error occurred (as described in the EB field).
    [11] ERI — Early Receive Interrupt This bit indicates that the DMA filled the first data buffer of the packet.
    [10] ETI — Early Transmit Interrupt This bit indicates that the packet to be transmitted is fully transferred to the MTL Tx FIFO.
    [9] RWT — Receive Watchdog time out This bit is asserted when a packet with length greater than 2,048 bytes (10,240 bytes when Jumbo Packet mode is enabled) is received.
    [8] RPS — Receive Process Stopped This bit is asserted when the Rx process enters the Stopped state.
    [7] RBU — Receive Buffer Unavailable This bit indicates that the application owns the next in the receive list, and the DMA cannot acquire it.
    [6] RI — Receive Interrupt This bit indicates that the packet reception is complete.
    [2] TBU — Transmit Buffer Unavailable This bit indicates that the application owns the next descriptor in the transmit list, and the DMA cannot acquire it.
    [1] TPS — Transmit Process Stopped This bit is set when the transmission is stopped.
    [0] TI — Transmit Interrupt This bit indicates that the packet transmission is complete.
  0x6C DMA_CHx_MISS_FRAME_CNT — Channelx missed frame count.
    [15] MFCO — Overflow status of the MFC counter.
    [10:0] MFC ro — Dropped packet counters.
